# ESP32-H2 register map
Vendor: ESPRESSIF SYSTEMS (SHANGHAI) CO., LTD.; Series: ESP32 H-Series; File version: 12
CPU: RV32IMAC r0p0, little endian, no MPU, no FPU, 0 interrupt priority bits
Address unit: 32 bits
Registers are 32-bit, read-write, reset 0x0 unless marked. A register's access mark holds for its fields unless they carry their own. Offsets are from the block's base; [hi:lo] are bit positions; lines under a group give offsets from that group; {n}, {i} and the like mark numbered series.

## MCPWM0 — Motor Control Pulse Width Modulator (MCPWM) Peripheral
Base 0x60014000
0x00 CLK_CFG — PWM clock prescaler register.
  [7:0] CLK_PRESCALE — Period of PWM_clk = 6.25ns * (PWM_CLK_PRESCALE + 1)
{0x4+0x10*i} TIMER{i} (i=0..2) group — Cluster TIMER{i}, containing TIMER?_CFG0, TIMER?_CFG1, TIMER?_SYNC, TIMER?_STATUS
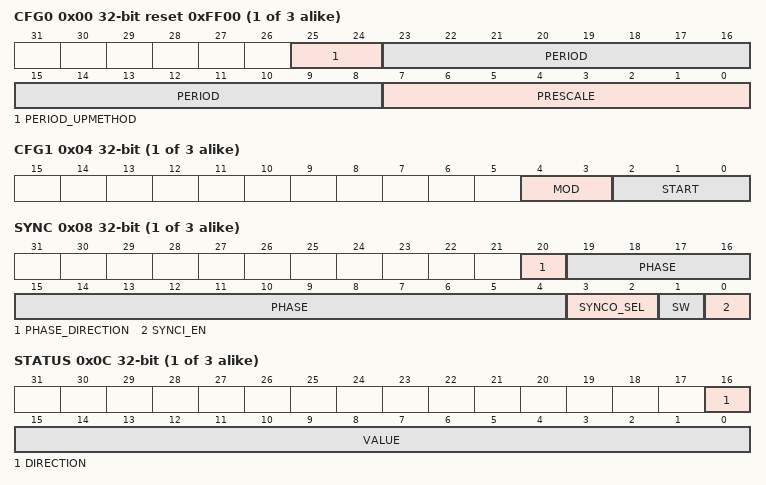
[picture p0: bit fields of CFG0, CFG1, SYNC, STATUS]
  0x00 CFG0 reset 0xFF00 — PWM TIMERx period and update method configuration register.
    [25:24] PERIOD_UPMETHOD — Update method for active register of PWM timer0 period, 0: immediate, 1: TEZ, 2: sync, 3: TEZ | sync. TEZ here and below means timer equal zero event
    [23:8] PERIOD — period shadow register of PWM timer0
    [7:0] PRESCALE — period of PT0_clk = Period of PWM_clk * (PWM_TIMER0_PRESCALE + 1)
  0x04 CFG1 — PWM TIMERx working mode and start/stop control configuration register.
    [4:3] MOD — PWM timer0 working mode, 0: freeze, 1: increase mode, 2: decrease mode, 3: up-down mode
    [2:0] START — PWM timer0 start and stop control. 0: if PWM timer0 starts, then stops at TEZ, 1: if timer0 starts, then stops at TEP, 2: PWM timer0 starts and runs on, 3: timer0 starts and stops at the next TEZ, 4: timer0 starts and stops at the next TEP. TEP here and below means the event that happens when the timer equals to period
  0x08 SYNC — PWM TIMERx sync function configuration register.
    [20] PHASE_DIRECTION — Configure the PWM timer0's direction when timer0 mode is up-down mode: 0-increase,1-decrease
    [19:4] PHASE — phase for timer reload on sync event
    [3:2] SYNCO_SEL — PWM timer0 sync_out selection, 0: sync_in, 1: TEZ, 2: TEP, and sync out will always generate when toggling the reg_timer0_sync_sw bit
    [1] SW — Toggling this bit will trigger a software sync.
    [0] SYNCI_EN — When set, timer reloading with phase on sync input event is enabled.
  0x0C STATUS ro — PWM TIMERx status register.
    [16] DIRECTION — current PWM timer0 counter direction, 0: increment 1: decrement
    [15:0] VALUE — current PWM timer0 counter value
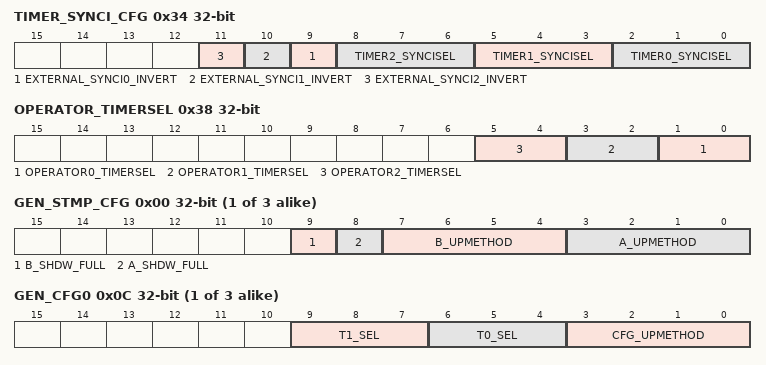
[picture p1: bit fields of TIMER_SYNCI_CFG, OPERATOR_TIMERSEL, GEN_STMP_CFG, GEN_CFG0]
0x34 TIMER_SYNCI_CFG — Synchronization input selection for three PWM timers.
  [n+9] EXTERNAL_SYNCI{n}_INVERT (n=0..2) — invert SYNC{n} from GPIO matrix
  [3n+2:3n] TIMER{n}_SYNCISEL (n=0..2) — select sync input for PWM timer{n}, 1: PWM timer0 sync_out, 2: PWM timer1 sync_out, 3: PWM timer2 sync_out, 4: SYNC0 from GPIO matrix, 5: SYNC1 from GPIO matrix, 6: SYNC2 from GPIO matrix, other values: no sync input selected
0x38 OPERATOR_TIMERSEL — Select specific timer for PWM operators.
  [2n+1:2n] OPERATOR{n}_TIMERSEL (n=0..2) — Select which PWM timer's is the timing reference for PWM operator{n}, 0: timer0, 1: timer1, 2: timer2
{0x3C+0x38*i} CH{i} (i=0..2) group — Cluster CH{i}, containing GEN?_STMP_CFG, GEN?_TSTMP_A, GEN?_TSTMP_B, GEN?_CFG0, GEN?_FORCE, GEN?_A, GEN?_B, DT?_CFG, DT?_FED_CFG, DT?_RED_CFG, CARRIER?_CFG, FH?_CFG0, FH?_CFG1, FH?_STATUS
  0x00 GEN_STMP_CFG — Transfer status and update method for time stamp registers A and B
    [9] B_SHDW_FULL — Set and reset by hardware. If set, PWM generator 0 time stamp B's shadow reg is filled and waiting to be transferred to B's active reg. If cleared, B's active reg has been updated with shadow register latest value
    [8] A_SHDW_FULL — Set and reset by hardware. If set, PWM generator 0 time stamp A's shadow reg is filled and waiting to be transferred to A's active reg. If cleared, A's active reg has been updated with shadow register latest value
    [7:4] B_UPMETHOD — Update method for PWM generator 0 time stamp B's active register. When all bits are set to 0: immediately, when bit0 is set to 1: TEZ, when bit1 is set to 1: TEP,when bit2 is set to 1: sync, when bit3 is set to 1: disable the update.
    [3:0] A_UPMETHOD — Update method for PWM generator 0 time stamp A's active register. When all bits are set to 0: immediately, when bit0 is set to 1: TEZ, when bit1 is set to 1: TEP,when bit2 is set to 1: sync, when bit3 is set to 1: disable the update.
  0x04 GEN_TSTMP_A — Shadow register for register A.
    [15:0] A — PWM generator 0 time stamp A's shadow register
  0x08 GEN_TSTMP_B — Shadow register for register B.
    [15:0] B — PWM generator 0 time stamp B's shadow register
  0x0C GEN_CFG0 — Fault event T0 and T1 handling
    [9:7] T1_SEL — Source selection for PWM generator 0 event_t1, take effect immediately, 0: fault_event0, 1: fault_event1, 2: fault_event2, 3: sync_taken, 4: none
    [6:4] T0_SEL — Source selection for PWM generator 0 event_t0, take effect immediately, 0: fault_event0, 1: fault_event1, 2: fault_event2, 3: sync_taken, 4: none
    [3:0] CFG_UPMETHOD — Update method for PWM generator 0's active register of configuration. When all bits are set to 0: immediately, when bit0 is set to 1: TEZ, when bit1 is set to 1:TEP,when bit2 is set to 1:sync,when bit3 is set to 1:disable the update
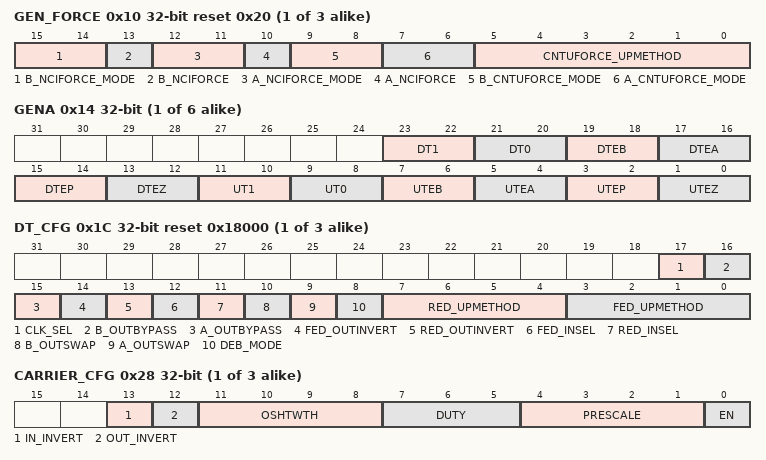
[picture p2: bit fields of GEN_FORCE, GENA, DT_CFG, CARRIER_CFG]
  0x10 GEN_FORCE reset 0x20 — Permissives to force PWMxA and PWMxB outputs by software
    [15:14] B_NCIFORCE_MODE — non-continuous immediate software force mode for PWM0B, 0: disabled, 1: low, 2: high, 3: disabled
    [13] B_NCIFORCE — Trigger of non-continuous immediate software-force event for PWM0B, a toggle will trigger a force event.
    [12:11] A_NCIFORCE_MODE — non-continuous immediate software force mode for PWM0A, 0: disabled, 1: low, 2: high, 3: disabled
    [10] A_NCIFORCE — Trigger of non-continuous immediate software-force event for PWM0A, a toggle will trigger a force event.
    [9:8] B_CNTUFORCE_MODE — Continuous software force mode for PWM0B. 0: disabled, 1: low, 2: high, 3: disabled
    [7:6] A_CNTUFORCE_MODE — Continuous software force mode for PWM0A. 0: disabled, 1: low, 2: high, 3: disabled
    [5:0] CNTUFORCE_UPMETHOD — Updating method for continuous software force of PWM generator0. When all bits are set to 0: immediately, when bit0 is set to 1: TEZ,,when bit1 is set to 1: TEP, when bit2 is set to 1: TEA, when bit3 is set to 1: TEB, when bit4 is set to 1: sync, when bit5 is set to 1: disable update. (TEA/B here and below means an event generated when the timer's value equals to that of register A/B.)
  0x14 GEN{x} (x=A,B; step 0x4) — Actions triggered by events on PWMx{x}
    [23:22] DT1 — Action on PWM0A triggered by event_t1 when timer decreasing. 0: no change, 1: low, 2: high, 3: toggle
    [21:20] DT0 — Action on PWM0A triggered by event_t0 when timer decreasing
    [19:18] DTEB — Action on PWM0A triggered by event TEB when timer decreasing
    [17:16] DTEA — Action on PWM0A triggered by event TEA when timer decreasing
    [15:14] DTEP — Action on PWM0A triggered by event TEP when timer decreasing
    [13:12] DTEZ — Action on PWM0A triggered by event TEZ when timer decreasing
    [11:10] UT1 — Action on PWM0A triggered by event_t1 when timer increasing
    [9:8] UT0 — Action on PWM0A triggered by event_t0 when timer increasing
    [7:6] UTEB — Action on PWM0A triggered by event TEB when timer increasing
    [5:4] UTEA — Action on PWM0A triggered by event TEA when timer increasing
    [3:2] UTEP — Action on PWM0A triggered by event TEP when timer increasing
    [1:0] UTEZ — Action on PWM0A triggered by event TEZ when timer increasing
  0x1C DT_CFG reset 0x18000 — Dead time type selection and configuration
    [17] CLK_SEL — Dead time generator 0 clock selection. 0: PWM_clk, 1: PT_clk
    [16] B_OUTBYPASS — S0 in table
    [15] A_OUTBYPASS — S1 in table
    [14] FED_OUTINVERT — S3 in table
    [13] RED_OUTINVERT — S2 in table
    [12] FED_INSEL — S5 in table
    [11] RED_INSEL — S4 in table
    [10] B_OUTSWAP — S7 in table
    [9] A_OUTSWAP — S6 in table
    [8] DEB_MODE — S8 in table, dual-edge B mode, 0: fed/red take effect on different path separately, 1: fed/red take effect on B path, A out is in bypass or dulpB mode
    [7:4] RED_UPMETHOD — Update method for RED (rising edge delay) active register. 0: immediate, when bit0 is set to 1: tez, when bit1 is set to 1:tep, when bit2 is set to 1: sync, when bit3 is set to 1: disable the update
    [3:0] FED_UPMETHOD — Update method for FED (rising edge delay) active register. 0: immediate, when bit0 is set to 1: tez, when bit1 is set to 1:tep, when bit2 is set to 1: sync, when bit3 is set to 1: disable the update
  0x20 DT_FED_CFG — Shadow register for falling edge delay (FED).
    [15:0] FED — Shadow register for FED
  0x24 DT_RED_CFG — Shadow register for rising edge delay (RED).
    [15:0] RED — Shadow register for RED
  0x28 CARRIER_CFG — Carrier enable and configuratoin
    [13] IN_INVERT — when set, invert the input of PWM0A and PWM0B for this submodule
    [12] OUT_INVERT — when set, invert the output of PWM0A and PWM0B for this submodule
    [11:8] OSHTWTH — width of the first pulse in number of periods of the carrier
    [7:5] DUTY — carrier duty selection. Duty = PWM_CARRIER0_DUTY / 8
    [4:1] PRESCALE — PWM carrier0 clock (PC_clk) prescale value. Period of PC_clk = period of PWM_clk * (PWM_CARRIER0_PRESCALE + 1)
    [0] EN — When set, carrier0 function is enabled. When cleared, carrier0 is bypassed
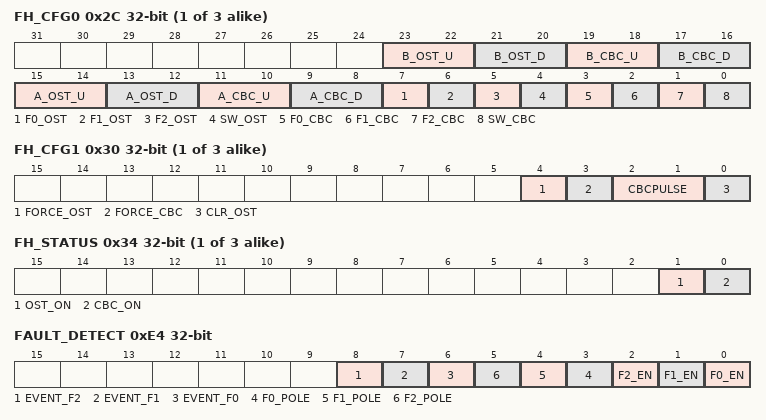
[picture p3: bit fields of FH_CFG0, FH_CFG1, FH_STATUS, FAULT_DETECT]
  0x2C FH_CFG0 — Actions on PWM0A and PWM0B trip events
    [23:22] B_OST_U — One-shot mode action on PWM0B when fault event occurs and timer is increasing. 0: do nothing, 1: force low, 2: force high, 3: toggle
    [21:20] B_OST_D — One-shot mode action on PWM0B when fault event occurs and timer is decreasing. 0: do nothing, 1: force low, 2: force high, 3: toggle
    [19:18] B_CBC_U — Cycle-by-cycle mode action on PWM0B when fault event occurs and timer is increasing. 0: do nothing,1: force low, 2: force high, 3: toggle
    [17:16] B_CBC_D — Cycle-by-cycle mode action on PWM0B when fault event occurs and timer is decreasing. 0: do nothing, 1: force low, 2: force high, 3: toggle
    [15:14] A_OST_U — One-shot mode action on PWM0A when fault event occurs and timer is increasing. 0: do nothing, 1: force low, 2: force high, 3: toggle
    [13:12] A_OST_D — One-shot mode action on PWM0A when fault event occurs and timer is decreasing. 0: do nothing, 1: force low, 2: force high, 3: toggle
    [11:10] A_CBC_U — Cycle-by-cycle mode action on PWM0A when fault event occurs and timer is increasing. 0: do nothing, 1: force low, 2: force high, 3: toggle
    [9:8] A_CBC_D — Cycle-by-cycle mode action on PWM0A when fault event occurs and timer is decreasing. 0: do nothing, 1: force low, 2: force high, 3: toggle
    [7] F0_OST — event_f0 will trigger one-shot mode action. 0: disable, 1: enable
    [6] F1_OST — event_f1 will trigger one-shot mode action. 0: disable, 1: enable
    [5] F2_OST — event_f2 will trigger one-shot mode action. 0: disable, 1: enable
    [4] SW_OST — Enable register for software force one-shot mode action. 0: disable, 1: enable
    [3] F0_CBC — event_f0 will trigger cycle-by-cycle mode action. 0: disable, 1: enable
    [2] F1_CBC — event_f1 will trigger cycle-by-cycle mode action. 0: disable, 1: enable
    [1] F2_CBC — event_f2 will trigger cycle-by-cycle mode action. 0: disable, 1: enable
    [0] SW_CBC — Enable register for software force cycle-by-cycle mode action. 0: disable, 1: enable
  0x30 FH_CFG1 — Software triggers for fault handler actions
    [4] FORCE_OST — a toggle (software negate its value) triggers a one-shot mode action
    [3] FORCE_CBC — a toggle trigger a cycle-by-cycle mode action
    [2:1] CBCPULSE — cycle-by-cycle mode action refresh moment selection. When bit0 is set to 1: TEZ, when bit1 is set to 1:TEP
    [0] CLR_OST — a rising edge will clear on going one-shot mode action
  0x34 FH_STATUS ro — Status of fault events.
    [1] OST_ON — Set and reset by hardware. If set, an one-shot mode action is on going
    [0] CBC_ON — Set and reset by hardware. If set, a cycle-by-cycle mode action is on going
0xE4 FAULT_DETECT access per field — Fault detection configuration and status
  [8] EVENT_F2 ro — Set and reset by hardware. If set, event_f2 is on going
  [7] EVENT_F1 ro — Set and reset by hardware. If set, event_f1 is on going
  [6] EVENT_F0 ro — Set and reset by hardware. If set, event_f0 is on going
  [n+3] F{n}_POLE (n=0..2) rw — Configures the polarity of the fault trigger on FAULT{n} source from GPIO matrix.\0: Level low\1: Level high
  [n] F{n}_EN (n=0..2) rw — When set, event_f{n} generation is enabled
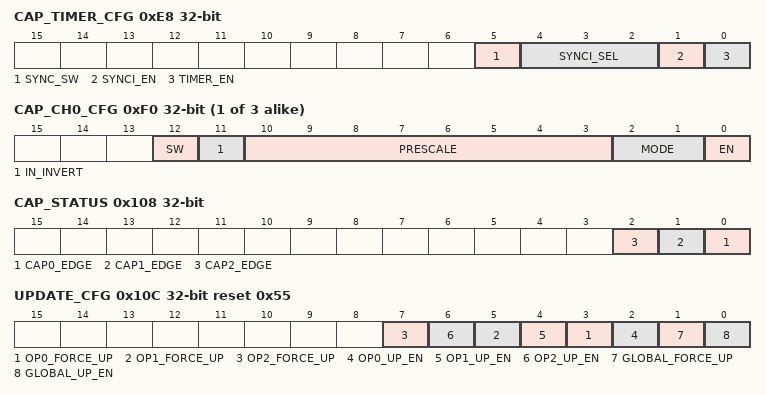
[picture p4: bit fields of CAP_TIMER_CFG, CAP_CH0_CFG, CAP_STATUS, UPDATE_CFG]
0xE8 CAP_TIMER_CFG access per field — Configure capture timer
  [5] SYNC_SW wo — When reg_cap_synci_en is 1, write 1 will trigger a capture timer sync, capture timer is loaded with value in phase register.
  [4:2] SYNCI_SEL rw — capture module sync input selection. 0: none, 1: timer0 sync_out, 2: timer1 sync_out, 3: timer2 sync_out, 4: SYNC0 from GPIO matrix, 5: SYNC1 from GPIO matrix, 6: SYNC2 from GPIO matrix
  [1] SYNCI_EN rw — When set, capture timer sync is enabled.
  [0] TIMER_EN rw — When set, capture timer incrementing under APB_clk is enabled.
0xEC CAP_TIMER_PHASE — Phase for capture timer sync
  [31:0] PHASE — Phase value for capture timer sync operation.
{0xF0+4i} CAP_CH{i}_CFG (i=0..2) access per field — Capture channel {i} configuration and enable
  [12] SW wo — Write 1 will trigger a software forced capture on channel 0
  [11] IN_INVERT rw — when set, CAP0 form GPIO matrix is inverted before prescale
  [10:3] PRESCALE rw — Value of prescaling on possitive edge of CAP0. Prescale value = PWM_CAP0_PRESCALE + 1
  [2:1] MODE rw — Describes which edges to trigger a capture event
    0=None (Capture nothing); 1=FallingEdge (Capture falling edges); 2=RisingEdge (Capture rising edges); 3=AnyEdge (Capture any edges)
  [0] EN rw — When set, capture on channel 0 is enabled
{0xFC+4i} CAP_CH{i} (i=0..2) ro — Value of last capture on channel {i}
  [31:0] VALUE
0x108 CAP_STATUS ro — Edge of last capture trigger
  [n] CAP{n}_EDGE (n=0..2) — Describes the last captured edge on channel{n}.
    0=Rising edge; 1=Falling edge
0x10C UPDATE_CFG reset 0x55 — Enable update.
  [2n+3] OP{n}_FORCE_UP (n=0..2) — A toggle (software invert its value) will trigger a forced update of active registers in PWM operator {n}
  [2n+2] OP{n}_UP_EN (n=0..2) — When set and PWM_GLOBAL_UP_EN is set, update of active registers in PWM operator {n} are enabled
  [1] GLOBAL_FORCE_UP — a toggle (software invert its value) will trigger a forced update of all active registers in MCPWM module
  [0] GLOBAL_UP_EN — The global enable of update of all active registers in MCPWM module
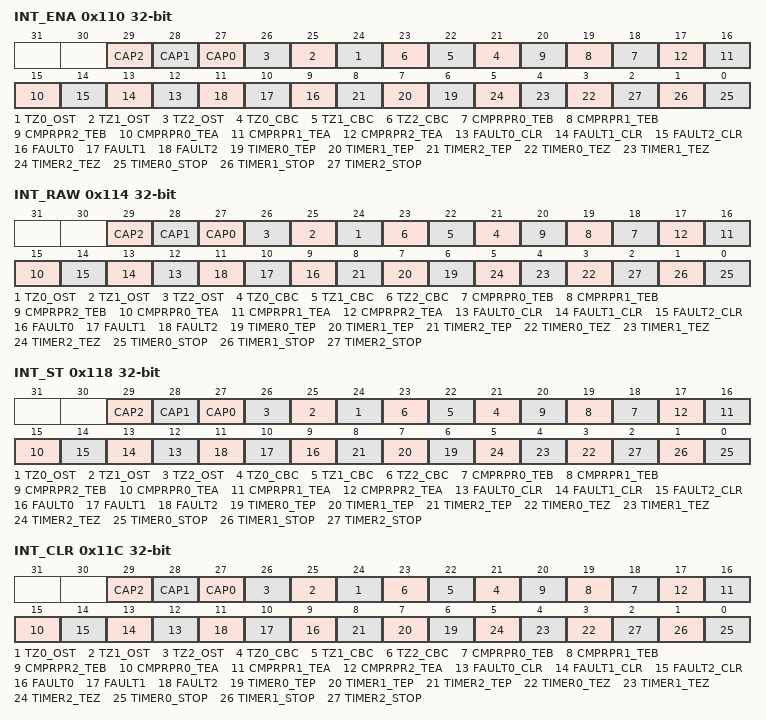
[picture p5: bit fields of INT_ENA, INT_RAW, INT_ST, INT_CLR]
0x110 INT_ENA — Interrupt enable bits
  [n+27] CAP{n} (n=0..2) — The interrupt enable bit for the capture{n} event.
  [n+24] TZ{n}_OST (n=0..2) — The interrupt enable bit for the fault handler{n} one-shot mode action.
  [n+21] TZ{n}_CBC (n=0..2) — The interrupt enable bit for the fault handler{n} cycle-by-cycle mode action.
  [18] CMPR{x}_TEB (x=PR0,PR1,PR2; step 1) — The interrupt enable bit for the operator{x} compare B event.
  [15] CMPR{x}_TEA (x=PR0,PR1,PR2; step 1) — The interrupt enable bit for the operator{x} compare A event.
  [n+12] FAULT{n}_CLR (n=0..2) — The interrupt enable bit for the fault{n} clear event.
  [n+9] FAULT{n} (n=0..2) — The interrupt enable bit for the fault{n} event.
  [n+6] TIMER{n}_TEP (n=0..2) — The interrupt enable bit for the timer{n} period event.
  [n+3] TIMER{n}_TEZ (n=0..2) — The interrupt enable bit for the timer{n} zero event.
  [n] TIMER{n}_STOP (n=0..2) — The interrupt enable bit for the timer{n} stop event.
0x114 INT_RAW — Raw interrupt status
  [n+27] CAP{n} (n=0..2) — The interrupt raw bit for the capture{n} event.
  [n+24] TZ{n}_OST (n=0..2) — The interrupt raw bit for the fault handler{n} one-shot mode action.
  [n+21] TZ{n}_CBC (n=0..2) — The interrupt raw bit for the fault handler{n} cycle-by-cycle mode action.
  [18] CMPR{x}_TEB (x=PR0,PR1,PR2; step 1) — The interrupt raw bit for the operator{x} compare B event.
  [15] CMPR{x}_TEA (x=PR0,PR1,PR2; step 1) — The interrupt raw bit for the operator{x} compare A event.
  [n+12] FAULT{n}_CLR (n=0..2) — The interrupt raw bit for the fault{n} clear event.
  [n+9] FAULT{n} (n=0..2) — The interrupt raw bit for the fault{n} event.
  [n+6] TIMER{n}_TEP (n=0..2) — The interrupt raw bit for the timer{n} period event.
  [n+3] TIMER{n}_TEZ (n=0..2) — The interrupt raw bit for the timer{n} zero event.
  [n] TIMER{n}_STOP (n=0..2) — The interrupt raw bit for the timer{n} stop event.
0x118 INT_ST ro — Masked interrupt status
  [n+27] CAP{n} (n=0..2) — The interrupt status bit for the capture{n} event.
  [n+24] TZ{n}_OST (n=0..2) — The interrupt status bit for the fault handler{n} one-shot mode action.
  [n+21] TZ{n}_CBC (n=0..2) — The interrupt status bit for the fault handler{n} cycle-by-cycle mode action.
  [18] CMPR{x}_TEB (x=PR0,PR1,PR2; step 1) — The interrupt status bit for the operator{x} compare B event.
  [15] CMPR{x}_TEA (x=PR0,PR1,PR2; step 1) — The interrupt status bit for the operator{x} compare A event.
  [n+12] FAULT{n}_CLR (n=0..2) — The interrupt status bit for the fault{n} clear event.
  [n+9] FAULT{n} (n=0..2) — The interrupt status bit for the fault{n} event.
  [n+6] TIMER{n}_TEP (n=0..2) — The interrupt status bit for the timer{n} period event.
  [n+3] TIMER{n}_TEZ (n=0..2) — The interrupt status bit for the timer{n} zero event.
  [n] TIMER{n}_STOP (n=0..2) — The interrupt status bit for the timer{n} stop event.
0x11C INT_CLR wo — Interrupt clear bits
  [n+27] CAP{n} (n=0..2) write-1-clears — The interrupt clear bit for the capture{n} event.
  [n+24] TZ{n}_OST (n=0..2) write-1-clears — The interrupt clear bit for the fault handler{n} one-shot mode action.
  [n+21] TZ{n}_CBC (n=0..2) write-1-clears — The interrupt clear bit for the fault handler{n} cycle-by-cycle mode action.
  [18] CMPR{x}_TEB (x=PR0,PR1,PR2; step 1) write-1-clears — The interrupt clear bit for the operator{x} compare B event.
  [15] CMPR{x}_TEA (x=PR0,PR1,PR2; step 1) write-1-clears — The interrupt clear bit for the operator{x} compare A event.
  [n+12] FAULT{n}_CLR (n=0..2) write-1-clears — The interrupt clear bit for the fault{n} clear event.
  [n+9] FAULT{n} (n=0..2) write-1-clears — The interrupt clear bit for the fault{n} event.
  [n+6] TIMER{n}_TEP (n=0..2) write-1-clears — The interrupt clear bit for the timer{n} period event.
  [n+3] TIMER{n}_TEZ (n=0..2) write-1-clears — The interrupt clear bit for the timer{n} zero event.
  [n] TIMER{n}_STOP (n=0..2) write-1-clears — The interrupt clear bit for the timer{n} stop event.
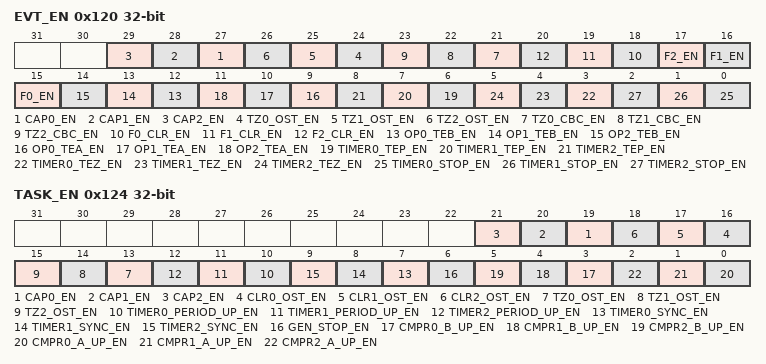
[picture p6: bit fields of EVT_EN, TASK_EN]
0x120 EVT_EN — MCPWM event enable register
  [n+27] CAP{n}_EN (n=0..2) — set this bit high to enable capture{n} event generate
  [n+24] TZ{n}_OST_EN (n=0..2) — set this bit high to enable one shot trip{n} event generate
  [n+21] TZ{n}_CBC_EN (n=0..2) — set this bit high to enable cycle by cycle trip{n} event generate
  [n+18] F{n}_CLR_EN (n=0..2) — set this bit high to enable fault{n} clear event generate
  [n+15] F{n}_EN (n=0..2) — set this bit high to enable fault{n} event generate
  [n+12] OP{n}_TEB_EN (n=0..2) — set this bit high to enable PWM generator{n} timer equal b event generate
  [n+9] OP{n}_TEA_EN (n=0..2) — set this bit high to enable PWM generator{n} timer equal a event generate
  [n+6] TIMER{n}_TEP_EN (n=0..2) — set this bit high to enable timer{n} equal period event generate
  [n+3] TIMER{n}_TEZ_EN (n=0..2) — set this bit high to enable timer{n} equal zero event generate
  [n] TIMER{n}_STOP_EN (n=0..2) — set this bit high to enable timer{n} stop event generate
0x124 TASK_EN — MCPWM task enable register
  [n+19] CAP{n}_EN (n=0..2) — set this bit high to enable capture{n} task receive
  [n+16] CLR{n}_OST_EN (n=0..2) — set this bit high to enable one shot trip{n} clear task receive
  [n+13] TZ{n}_OST_EN (n=0..2) — set this bit high to enable one shot trip{n} task receive
  [n+10] TIMER{n}_PERIOD_UP_EN (n=0..2) — set this bit high to enable timer{n} period update task receive
  [n+7] TIMER{n}_SYNC_EN (n=0..2) — set this bit high to enable timer{n} sync task receive
  [6] GEN_STOP_EN — set this bit high to enable all PWM generate stop task receive
  [n+3] CMPR{n}_B_UP_EN (n=0..2) — set this bit high to enable PWM generator{n} timer stamp B's shadow register update task receive
  [n] CMPR{n}_A_UP_EN (n=0..2) — set this bit high to enable PWM generator{n} timer stamp A's shadow register update task receive
0x128 CLK — MCPWM APB configuration register
  [0] EN — Force clock on for this register file
0x12C VERSION
